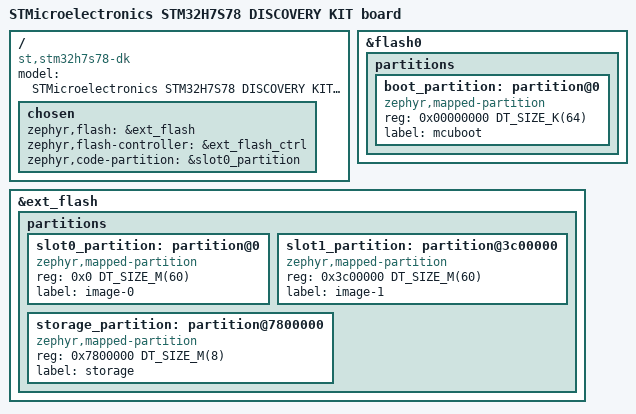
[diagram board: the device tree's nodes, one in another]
/*
 * Copyright (c) 2024-2025 STMicroelectronics
 *
 * SPDX-License-Identifier: Apache-2.0
 */

/dts-v1/;
#include "stm32h7s78_dk-common.dtsi"

/ {
	compatible = "st,stm32h7s78-dk";
	model = "STMicroelectronics STM32H7S78 DISCOVERY KIT board";

	chosen {
		zephyr,flash = &ext_flash;
		zephyr,flash-controller = &ext_flash_ctrl;
		zephyr,code-partition = &slot0_partition;
	};
};

&flash0 {
	partitions {
		ranges;
		#address-cells = <1>;
		#size-cells = <1>;

		boot_partition: partition@0 {
			compatible = "zephyr,mapped-partition";
			reg = <0x00000000 DT_SIZE_K(64)>;
			label = "mcuboot";
		};
	};
};

&ext_flash {
	status = "okay";

	partitions {
		ranges;
		#address-cells = <1>;
		#size-cells = <1>;

		slot0_partition: partition@0 {
			compatible = "zephyr,mapped-partition";
			reg = <0x0 DT_SIZE_M(60)>;
			label = "image-0";
		};

		slot1_partition: partition@3c00000 {
			compatible = "zephyr,mapped-partition";
			reg = <0x3c00000 DT_SIZE_M(60)>;
			label = "image-1";
		};

		storage_partition: partition@7800000 {
			compatible = "zephyr,mapped-partition";
			reg = <0x7800000 DT_SIZE_M(8)>;
			label = "storage";
		};
	};
};
